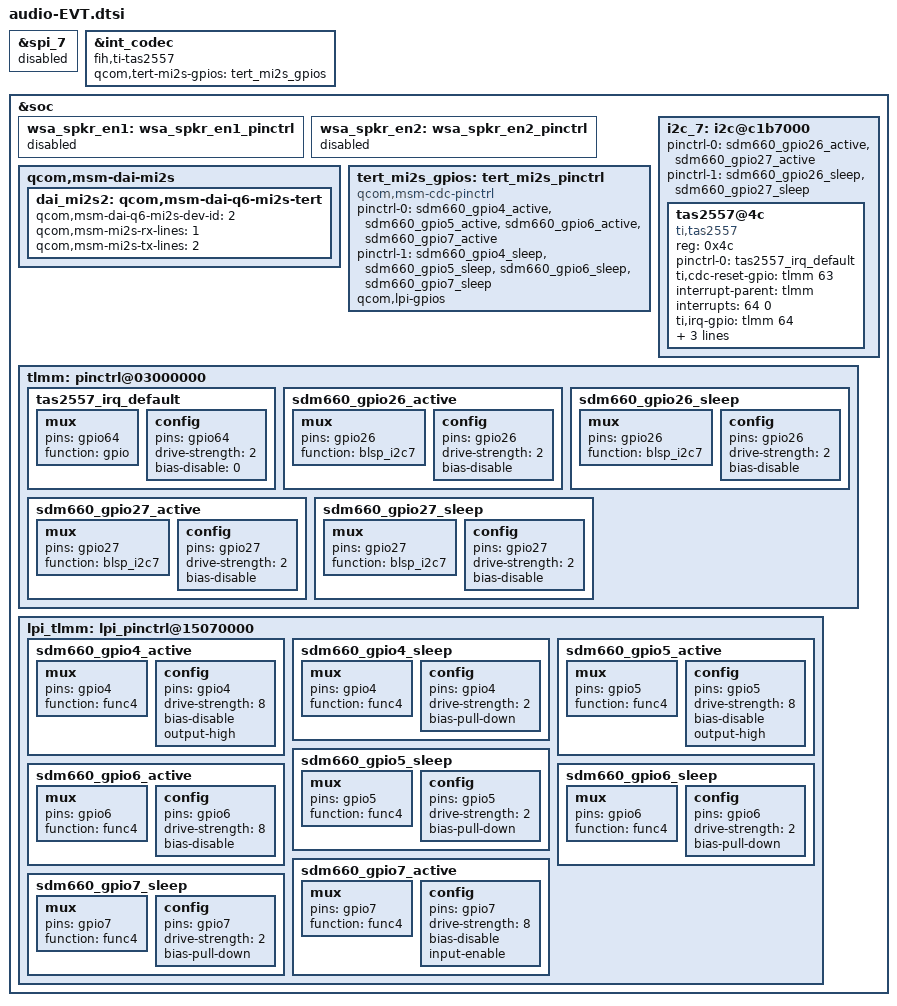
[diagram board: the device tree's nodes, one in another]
&spi_7 {
	status = "disabled";
};
#include <dt-bindings/input/ti-drv260x.h> //TI drv2605L include header


&int_codec {
  fih,ti-tas2557;
  qcom,tert-mi2s-gpios = <&tert_mi2s_gpios>;
};

&soc {

  /* Disable GPIO_26 for BLSP7_SDA pin */
	wsa_spkr_en1: wsa_spkr_en1_pinctrl {
		status = "disabled";
	};

  /* Disable GPIO_27 for BLSP7_SDA pin */
	wsa_spkr_en2: wsa_spkr_en2_pinctrl {
		status = "disabled";
	};


	/* TAS2557 SmartAmp I2S */
	qcom,msm-dai-mi2s {
		dai_mi2s2: qcom,msm-dai-q6-mi2s-tert {
			qcom,msm-dai-q6-mi2s-dev-id = <2>;
			qcom,msm-mi2s-rx-lines = <1>;
			qcom,msm-mi2s-tx-lines = <2>;
		};
	};

	tert_mi2s_gpios: tert_mi2s_pinctrl {
		compatible = "qcom,msm-cdc-pinctrl";
		pinctrl-names = "aud_active", "aud_sleep";
		pinctrl-0 = <&sdm660_gpio4_active &sdm660_gpio5_active &sdm660_gpio6_active &sdm660_gpio7_active>;
		pinctrl-1 = <&sdm660_gpio4_sleep &sdm660_gpio5_sleep &sdm660_gpio6_sleep &sdm660_gpio7_sleep>;
		qcom,lpi-gpios;
	};

	/* TAS2557 SmartAmp I2C */
	i2c_7: i2c@c1b7000 {
		pinctrl-names = "i2c_active", "i2c_sleep";
		pinctrl-0 = <&sdm660_gpio26_active &sdm660_gpio27_active>;
		pinctrl-1 = <&sdm660_gpio26_sleep &sdm660_gpio27_sleep>;
		status = "okay";
		
		tas2557@4c {
			compatible = "ti,tas2557";
			reg = <0x4c>;
		  pinctrl-names = "default";
		  pinctrl-0 = <&tas2557_irq_default>;
			ti,cdc-reset-gpio = <&tlmm 63 0>;
		  interrupt-parent = <&tlmm>;
		  interrupts = <64 0>;
			ti,irq-gpio = <&tlmm 64 0>;
			ti,i2s-bits = <16>;   /* support 16, 24, 32 */
			ti,bypass-tmax = <0>;   /* 0, not bypass; 1, bypass */
			tas2557,device-model = "B2N"; /* Select tas2557 firmware */
		};
	};

	/* gpio */
	tlmm: pinctrl@03000000 {
		  /* gpio 64 */ /* SMARTAMP_IRQ */
			tas2557_irq_default: tas2557_irq_default {
			mux {
				pins = "gpio64";
				function = "gpio";
			};

			config {
				pins = "gpio64";
				drive-strength = <2>;
				bias-disable = <0>;
			};
		};
	
		/* gpio 26 */ /* SPK_I2C_SDA */
		sdm660_gpio26_active: sdm660_gpio26_active {
			mux {
				pins = "gpio26";
				function = "blsp_i2c7";
			};

			config {
				pins = "gpio26";
				drive-strength = <2>;
				bias-disable;
			};
		};

		sdm660_gpio26_sleep: sdm660_gpio26_sleep {
			mux {
				pins = "gpio26";
				function = "blsp_i2c7";
			};

			config {
				pins = "gpio26";
				drive-strength = <2>;
				bias-disable;
			};
		};

		/* gpio 27 */ /* SPK_I2C_SCL */
		sdm660_gpio27_active: sdm660_gpio27_active {
			mux {
				pins = "gpio27";
				function = "blsp_i2c7";
			};

			config {
				pins = "gpio27";
				drive-strength = <2>;
				bias-disable;
			};
		};

		sdm660_gpio27_sleep: sdm660_gpio27_sleep {
			mux {
				pins = "gpio27";
				function = "blsp_i2c7";
			};

			config {
				pins = "gpio27";
				drive-strength = <2>;
				bias-disable;
			};
		};
	};

	lpi_tlmm: lpi_pinctrl@15070000 {
		/* gpio 4 */ /* SPK_I2S_CLK */
		sdm660_gpio4_active: sdm660_gpio4_active {
			mux {
				pins = "gpio4";
				function = "func4";
			};

			config {
				pins = "gpio4";
				drive-strength = <8>;
				bias-disable;
				output-high;
			};
		};

		sdm660_gpio4_sleep: sdm660_gpio4_sleep {
			mux {
				pins = "gpio4";
				function = "func4";
			};

			config {
				pins = "gpio4";
				drive-strength = <2>;
				bias-pull-down;
			};
		};

		/* gpio 5 */ /* SPK_I2S_WS */
		sdm660_gpio5_active: sdm660_gpio5_active {
			mux {
				pins = "gpio5";
				function = "func4";
			};

			config {
				pins = "gpio5";
				drive-strength = <8>;
				bias-disable;
				output-high;
			};
		};

		sdm660_gpio5_sleep: sdm660_gpio5_sleep {
			mux {
				pins = "gpio5";
				function = "func4";
			};

			config {
				pins = "gpio5";
				drive-strength = <2>;
				bias-pull-down;
			};
		};

		/* gpio 6 */ /* SPK_I2S_DATA0 */
		sdm660_gpio6_active: sdm660_gpio6_active {
			mux {
				pins = "gpio6";
				function = "func4";
			};

			config {
				pins = "gpio6";
				drive-strength = <8>;
				bias-disable;
			};
		};

		sdm660_gpio6_sleep: sdm660_gpio6_sleep {
			mux {
				pins = "gpio6";
				function = "func4";
			};

			config {
				pins = "gpio6";
				drive-strength = <2>;
				bias-pull-down;
			};
		};

		/* gpio 7 */ /* SPK_I2S_DATA1 */
		sdm660_gpio7_active: sdm660_gpio7_active {
			mux {
				pins = "gpio7";
				function = "func4";
			};

			config {
				pins = "gpio7";
				drive-strength = <8>;
				bias-disable;
				input-enable;
			};
		};

		sdm660_gpio7_sleep: sdm660_gpio7_sleep {
			mux {
				pins = "gpio7";
				function = "func4";
			};

			config {
				pins = "gpio7";
				drive-strength = <2>;
				bias-pull-down;
			};
		};
	};
};
